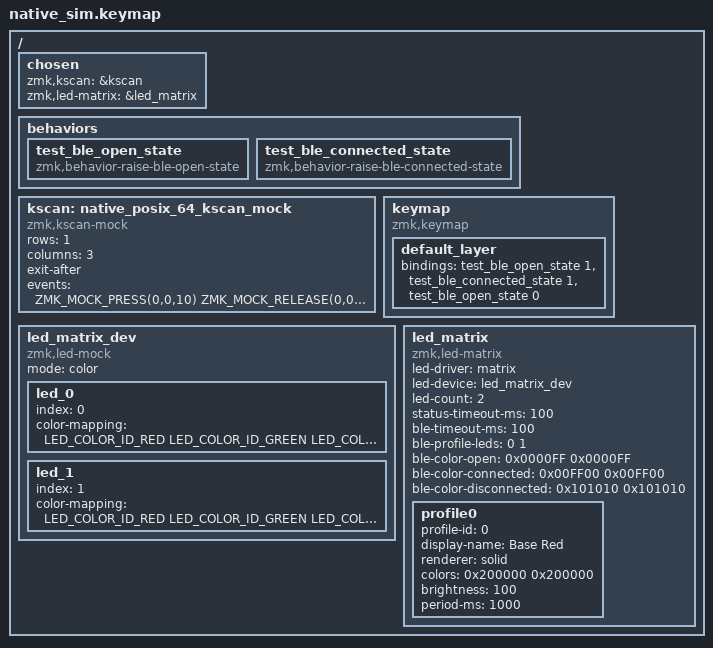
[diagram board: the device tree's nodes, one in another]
#include <dt-bindings/zmk/keys.h>
#include <dt-bindings/zmk/kscan_mock.h>
#include <dt-bindings/zmk/led_matrix.h>
#include <dt-bindings/led/led.h>
#include <behaviors.dtsi>

/ {
    chosen {
        zmk,kscan = &kscan;
        zmk,led-matrix = &led_matrix;
    };

    behaviors {
        test_ble_open_state: test_ble_open_state {
            compatible = "zmk,behavior-raise-ble-open-state";
            #binding-cells = <1>;
        };

        test_ble_connected_state: test_ble_connected_state {
            compatible = "zmk,behavior-raise-ble-connected-state";
            #binding-cells = <1>;
        };
    };

    kscan: native_posix_64_kscan_mock {
        compatible = "zmk,kscan-mock";
        rows = <1>;
        columns = <3>;
        exit-after;
        events = <
            ZMK_MOCK_PRESS(0,0,10)
            ZMK_MOCK_RELEASE(0,0,20)
            ZMK_MOCK_PRESS(0,1,220)
            ZMK_MOCK_RELEASE(0,1,20)
            ZMK_MOCK_PRESS(0,2,260)
            ZMK_MOCK_RELEASE(0,2,420)
        >;
    };

    keymap {
        compatible = "zmk,keymap";

        default_layer {
            bindings = <
                &test_ble_open_state 1
                &test_ble_connected_state 1
                &test_ble_open_state 0
            >;
        };
    };

    led_matrix_dev: led_matrix_dev {
        compatible = "zmk,led-mock";
        mode = "color";

        led_0 { index = <0>; color-mapping = <LED_COLOR_ID_RED LED_COLOR_ID_GREEN LED_COLOR_ID_BLUE>; };
        led_1 { index = <1>; color-mapping = <LED_COLOR_ID_RED LED_COLOR_ID_GREEN LED_COLOR_ID_BLUE>; };
    };

    led_matrix: led_matrix {
        compatible = "zmk,led-matrix";
        led-driver = "matrix";
        led-device = <&led_matrix_dev>;
        led-count = <2>;
        status-timeout-ms = <100>;
        ble-timeout-ms = <100>;
        ble-profile-leds = <0 1>;
        ble-color-open = <0x0000FF 0x0000FF>;
        ble-color-connected = <0x00FF00 0x00FF00>;
        ble-color-disconnected = <0x101010 0x101010>;

        profile0 {
            profile-id = <0>;
            display-name = "Base Red";
            renderer = "solid";
            colors = <0x200000 0x200000>;
            brightness = <100>;
            period-ms = <1000>;
        };
    };
};
